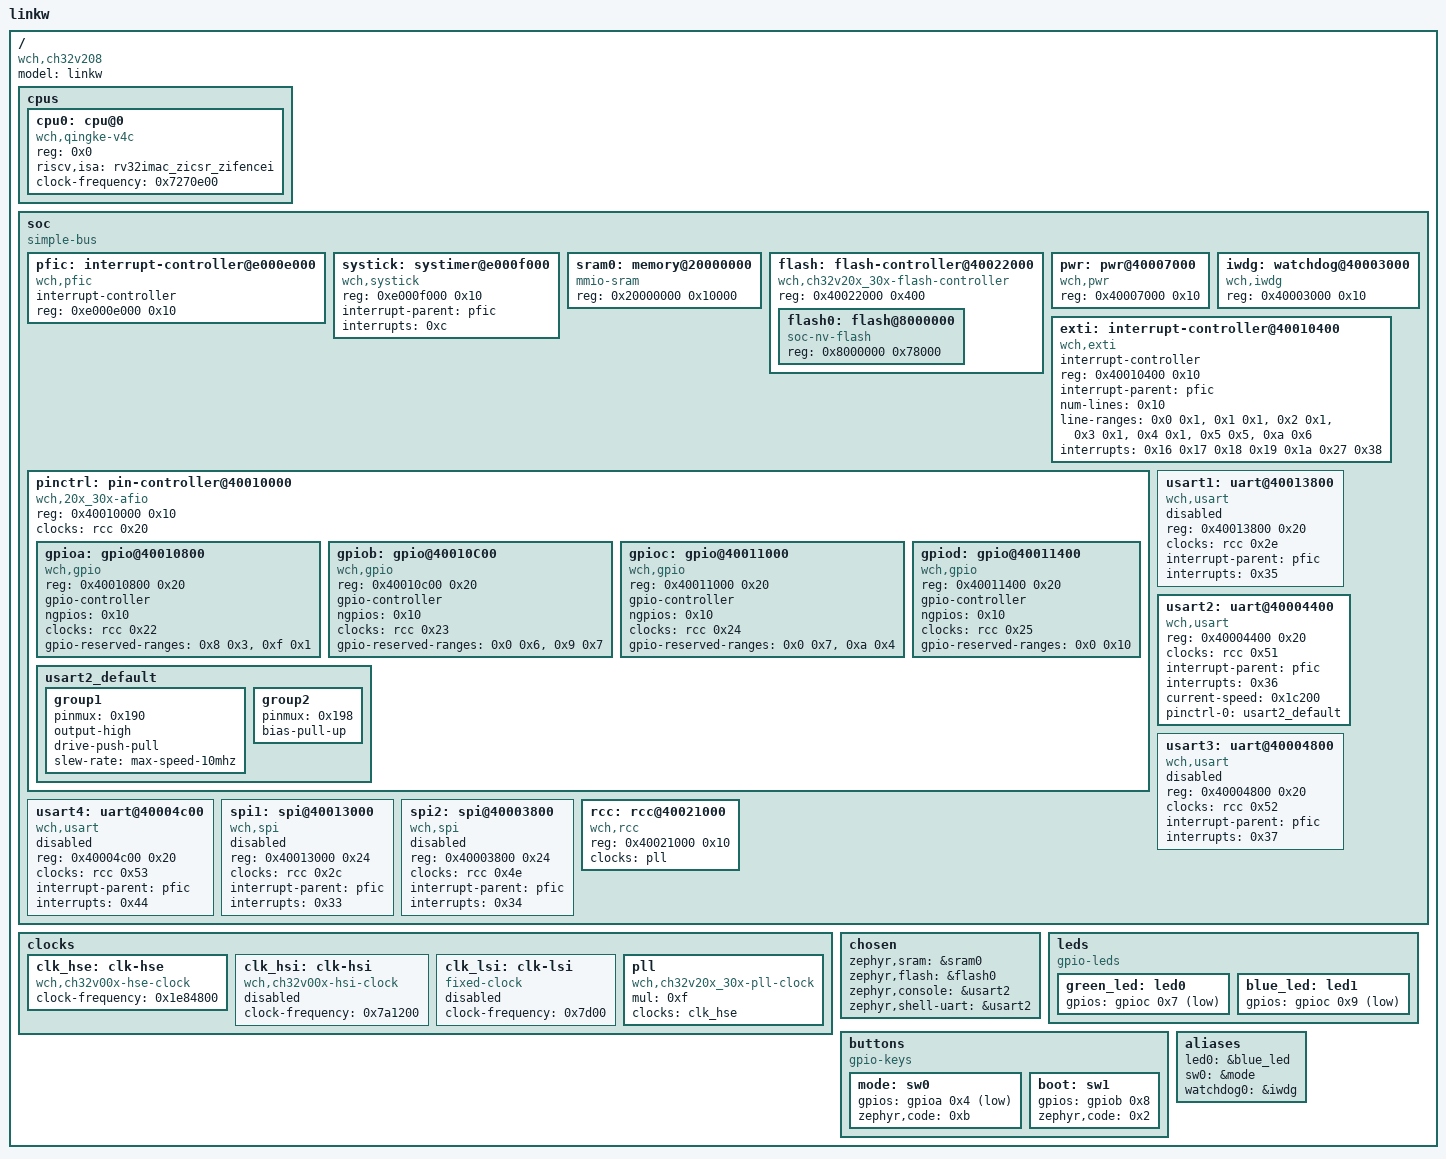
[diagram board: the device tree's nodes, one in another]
/dts-v1/;

/* node '/' defined in zephyr/dts/riscv/wch/qingke-v4c.dtsi:7 */
/ {
	#address-cells = < 0x1 >;    /* in zephyr/dts/riscv/wch/qingke-v4c.dtsi:8 */
	#size-cells = < 0x1 >;       /* in zephyr/dts/riscv/wch/qingke-v4c.dtsi:9 */
	model = "linkw";             /* in zephyr/boards/wch/linkw/linkw.dts:14 */
	compatible = "wch,ch32v208"; /* in zephyr/boards/wch/linkw/linkw.dts:15 */

	/* node '/cpus' defined in zephyr/dts/riscv/wch/qingke-v4c.dtsi:11 */
	cpus {
		#address-cells = < 0x1 >; /* in zephyr/dts/riscv/wch/qingke-v4c.dtsi:12 */
		#size-cells = < 0x0 >;    /* in zephyr/dts/riscv/wch/qingke-v4c.dtsi:13 */

		/* node '/cpus/cpu@0' defined in zephyr/dts/riscv/wch/qingke-v4c.dtsi:15 */
		cpu0: cpu@0 {
			device_type = "cpu";                   /* in zephyr/dts/riscv/wch/qingke-v4c.dtsi:16 */
			compatible = "wch,qingke-v4c";         /* in zephyr/dts/riscv/wch/qingke-v4c.dtsi:17 */
			reg = < 0x0 >;                         /* in zephyr/dts/riscv/wch/qingke-v4c.dtsi:18 */
			riscv,isa = "rv32imac_zicsr_zifencei"; /* in zephyr/dts/riscv/wch/qingke-v4c.dtsi:19 */
			clock-frequency = < 0x7270e00 >;       /* in zephyr/dts/riscv/wch/ch32v208/ch32v208.dtsi:200 */
		};
	};

	/* node '/soc' defined in zephyr/dts/riscv/wch/qingke-v4c.dtsi:23 */
	soc {
		#address-cells = < 0x1 >;  /* in zephyr/dts/riscv/wch/qingke-v4c.dtsi:24 */
		#size-cells = < 0x1 >;     /* in zephyr/dts/riscv/wch/qingke-v4c.dtsi:25 */
		compatible = "simple-bus"; /* in zephyr/dts/riscv/wch/qingke-v4c.dtsi:26 */
		ranges;                    /* in zephyr/dts/riscv/wch/qingke-v4c.dtsi:27 */

		/* node '/soc/interrupt-controller@e000e000' defined in zephyr/dts/riscv/wch/qingke-v4c.dtsi:29 */
		pfic: interrupt-controller@e000e000 {
			compatible = "wch,pfic";    /* in zephyr/dts/riscv/wch/qingke-v4c.dtsi:30 */
			#address-cells = < 0x0 >;   /* in zephyr/dts/riscv/wch/qingke-v4c.dtsi:31 */
			#interrupt-cells = < 0x1 >; /* in zephyr/dts/riscv/wch/qingke-v4c.dtsi:32 */
			interrupt-controller;       /* in zephyr/dts/riscv/wch/qingke-v4c.dtsi:33 */
			reg = < 0xe000e000 0x10 >;  /* in zephyr/dts/riscv/wch/qingke-v4c.dtsi:34 */
			status = "okay";            /* in zephyr/dts/riscv/wch/qingke-v4c.dtsi:35 */
			phandle = < 0x1 >;          /* in zephyr/dts/riscv/wch/qingke-v4c.dtsi:42 */
		};

		/* node '/soc/systimer@e000f000' defined in zephyr/dts/riscv/wch/qingke-v4c.dtsi:38 */
		systick: systimer@e000f000 {
			compatible = "wch,systick";   /* in zephyr/dts/riscv/wch/qingke-v4c.dtsi:39 */
			reg = < 0xe000f000 0x10 >;    /* in zephyr/dts/riscv/wch/qingke-v4c.dtsi:40 */
			status = "okay";              /* in zephyr/dts/riscv/wch/qingke-v4c.dtsi:41 */
			interrupt-parent = < &pfic >; /* in zephyr/dts/riscv/wch/qingke-v4c.dtsi:42 */
			interrupts = < 0xc >;         /* in zephyr/dts/riscv/wch/qingke-v4c.dtsi:43 */
		};

		/* node '/soc/memory@20000000' defined in zephyr/dts/riscv/wch/ch32v208/ch32v208.dtsi:46 */
		sram0: memory@20000000 {
			compatible = "mmio-sram";     /* in zephyr/dts/riscv/wch/ch32v208/ch32v208.dtsi:47 */
			reg = < 0x20000000 0x10000 >; /* in zephyr/dts/riscv/wch/ch32v208/ch32v208.dtsi:48 */
		};

		/* node '/soc/flash-controller@40022000' defined in zephyr/dts/riscv/wch/ch32v208/ch32v208.dtsi:51 */
		flash: flash-controller@40022000 {
			compatible = "wch,ch32v20x_30x-flash-controller"; /* in zephyr/dts/riscv/wch/ch32v208/ch32v208.dtsi:52 */
			reg = < 0x40022000 0x400 >;                       /* in zephyr/dts/riscv/wch/ch32v208/ch32v208.dtsi:53 */
			#address-cells = < 0x1 >;                         /* in zephyr/dts/riscv/wch/ch32v208/ch32v208.dtsi:54 */
			#size-cells = < 0x1 >;                            /* in zephyr/dts/riscv/wch/ch32v208/ch32v208.dtsi:55 */

			/* node '/soc/flash-controller@40022000/flash@8000000' defined in zephyr/dts/riscv/wch/ch32v208/ch32v208.dtsi:57 */
			flash0: flash@8000000 {
				compatible = "soc-nv-flash"; /* in zephyr/dts/riscv/wch/ch32v208/ch32v208.dtsi:58 */
				reg = < 0x8000000 0x78000 >; /* in zephyr/dts/riscv/wch/ch32v208/ch32v208.dtsi:59 */
			};
		};

		/* node '/soc/pwr@40007000' defined in zephyr/dts/riscv/wch/ch32v208/ch32v208.dtsi:63 */
		pwr: pwr@40007000 {
			compatible = "wch,pwr";    /* in zephyr/dts/riscv/wch/ch32v208/ch32v208.dtsi:64 */
			reg = < 0x40007000 0x10 >; /* in zephyr/dts/riscv/wch/ch32v208/ch32v208.dtsi:65 */
		};

		/* node '/soc/watchdog@40003000' defined in zephyr/dts/riscv/wch/ch32v208/ch32v208.dtsi:68 */
		iwdg: watchdog@40003000 {
			compatible = "wch,iwdg";   /* in zephyr/dts/riscv/wch/ch32v208/ch32v208.dtsi:69 */
			reg = < 0x40003000 0x10 >; /* in zephyr/dts/riscv/wch/ch32v208/ch32v208.dtsi:70 */
			status = "okay";           /* in zephyr/boards/wch/linkw/linkw.dts:92 */
		};

		/* node '/soc/interrupt-controller@40010400' defined in zephyr/dts/riscv/wch/ch32v208/ch32v208.dtsi:74 */
		exti: interrupt-controller@40010400 {
			compatible = "wch,exti";                             /* in zephyr/dts/riscv/wch/ch32v208/ch32v208.dtsi:75 */
			interrupt-controller;                                /* in zephyr/dts/riscv/wch/ch32v208/ch32v208.dtsi:76 */
			#interrupt-cells = < 0x1 >;                          /* in zephyr/dts/riscv/wch/ch32v208/ch32v208.dtsi:77 */
			reg = < 0x40010400 0x10 >;                           /* in zephyr/dts/riscv/wch/ch32v208/ch32v208.dtsi:78 */
			interrupt-parent = < &pfic >;                        /* in zephyr/dts/riscv/wch/ch32v208/ch32v208.dtsi:79 */
			num-lines = < 0x10 >;                                /* in zephyr/dts/riscv/wch/ch32v208/ch32v208.dtsi:80 */
			line-ranges = < 0x0 0x1 >,
			              < 0x1 0x1 >,
			              < 0x2 0x1 >,
			              < 0x3 0x1 >,
			              < 0x4 0x1 >,
			              < 0x5 0x5 >,
			              < 0xa 0x6 >;                           /* in zephyr/dts/riscv/wch/ch32v208/ch32v208.dtsi:81 */
			interrupts = < 0x16 0x17 0x18 0x19 0x1a 0x27 0x38 >; /* in zephyr/dts/riscv/wch/ch32v208/ch32v208.dtsi:83 */
			interrupt-names = "line0",
			                  "line1",
			                  "line2",
			                  "line3",
			                  "line4",
			                  "line5-9",
			                  "line10-15";                       /* in zephyr/dts/riscv/wch/ch32v208/ch32v208.dtsi:84 */
			status = "okay";                                     /* in zephyr/boards/wch/linkw/linkw.dts:73 */
		};

		/* node '/soc/pin-controller@40010000' defined in zephyr/dts/riscv/wch/ch32v208/ch32v208.dtsi:89 */
		pinctrl: pin-controller@40010000 {
			compatible = "wch,20x_30x-afio"; /* in zephyr/dts/riscv/wch/ch32v208/ch32v208.dtsi:90 */
			reg = < 0x40010000 0x10 >;       /* in zephyr/dts/riscv/wch/ch32v208/ch32v208.dtsi:91 */
			#address-cells = < 0x1 >;        /* in zephyr/dts/riscv/wch/ch32v208/ch32v208.dtsi:92 */
			#size-cells = < 0x1 >;           /* in zephyr/dts/riscv/wch/ch32v208/ch32v208.dtsi:93 */
			clocks = < &rcc 0x20 >;          /* in zephyr/dts/riscv/wch/ch32v208/ch32v208.dtsi:94 */

			/* node '/soc/pin-controller@40010000/gpio@40010800' defined in zephyr/dts/riscv/wch/ch32v208/ch32v208.dtsi:96 */
			gpioa: gpio@40010800 {
				compatible = "wch,gpio";            /* in zephyr/dts/riscv/wch/ch32v208/ch32v208.dtsi:97 */
				reg = < 0x40010800 0x20 >;          /* in zephyr/dts/riscv/wch/ch32v208/ch32v208.dtsi:98 */
				gpio-controller;                    /* in zephyr/dts/riscv/wch/ch32v208/ch32v208.dtsi:99 */
				#gpio-cells = < 0x2 >;              /* in zephyr/dts/riscv/wch/ch32v208/ch32v208.dtsi:100 */
				ngpios = < 0x10 >;                  /* in zephyr/dts/riscv/wch/ch32v208/ch32v208.dtsi:101 */
				clocks = < &rcc 0x22 >;             /* in zephyr/dts/riscv/wch/ch32v208/ch32v208.dtsi:102 */
				gpio-reserved-ranges = < 0x8 0x3 >,
				                       < 0xf 0x1 >; /* in zephyr/dts/riscv/wch/ch32v208/ch32v208gbu.dtsi:10 */
				status = "okay";                    /* in zephyr/boards/wch/linkw/linkw.dts:77 */
				phandle = < 0x7 >;                  /* in zephyr/boards/wch/linkw/linkw.dts:41 */
			};

			/* node '/soc/pin-controller@40010000/gpio@40010C00' defined in zephyr/dts/riscv/wch/ch32v208/ch32v208.dtsi:105 */
			gpiob: gpio@40010C00 {
				compatible = "wch,gpio";            /* in zephyr/dts/riscv/wch/ch32v208/ch32v208.dtsi:106 */
				reg = < 0x40010c00 0x20 >;          /* in zephyr/dts/riscv/wch/ch32v208/ch32v208.dtsi:107 */
				gpio-controller;                    /* in zephyr/dts/riscv/wch/ch32v208/ch32v208.dtsi:108 */
				#gpio-cells = < 0x2 >;              /* in zephyr/dts/riscv/wch/ch32v208/ch32v208.dtsi:109 */
				ngpios = < 0x10 >;                  /* in zephyr/dts/riscv/wch/ch32v208/ch32v208.dtsi:110 */
				clocks = < &rcc 0x23 >;             /* in zephyr/dts/riscv/wch/ch32v208/ch32v208.dtsi:111 */
				gpio-reserved-ranges = < 0x0 0x6 >,
				                       < 0x9 0x7 >; /* in zephyr/dts/riscv/wch/ch32v208/ch32v208gbu.dtsi:14 */
				phandle = < 0x8 >;                  /* in zephyr/boards/wch/linkw/linkw.dts:46 */
			};

			/* node '/soc/pin-controller@40010000/gpio@40011000' defined in zephyr/dts/riscv/wch/ch32v208/ch32v208.dtsi:114 */
			gpioc: gpio@40011000 {
				compatible = "wch,gpio";            /* in zephyr/dts/riscv/wch/ch32v208/ch32v208.dtsi:115 */
				reg = < 0x40011000 0x20 >;          /* in zephyr/dts/riscv/wch/ch32v208/ch32v208.dtsi:116 */
				gpio-controller;                    /* in zephyr/dts/riscv/wch/ch32v208/ch32v208.dtsi:117 */
				#gpio-cells = < 0x2 >;              /* in zephyr/dts/riscv/wch/ch32v208/ch32v208.dtsi:118 */
				ngpios = < 0x10 >;                  /* in zephyr/dts/riscv/wch/ch32v208/ch32v208.dtsi:119 */
				clocks = < &rcc 0x24 >;             /* in zephyr/dts/riscv/wch/ch32v208/ch32v208.dtsi:120 */
				gpio-reserved-ranges = < 0x0 0x7 >,
				                       < 0xa 0x4 >; /* in zephyr/dts/riscv/wch/ch32v208/ch32v208gbu.dtsi:18 */
				status = "okay";                    /* in zephyr/boards/wch/linkw/linkw.dts:81 */
				phandle = < 0x6 >;                  /* in zephyr/boards/wch/linkw/linkw.dts:29 */
			};

			/* node '/soc/pin-controller@40010000/gpio@40011400' defined in zephyr/dts/riscv/wch/ch32v208/ch32v208.dtsi:123 */
			gpiod: gpio@40011400 {
				compatible = "wch,gpio";             /* in zephyr/dts/riscv/wch/ch32v208/ch32v208.dtsi:124 */
				reg = < 0x40011400 0x20 >;           /* in zephyr/dts/riscv/wch/ch32v208/ch32v208.dtsi:125 */
				gpio-controller;                     /* in zephyr/dts/riscv/wch/ch32v208/ch32v208.dtsi:126 */
				#gpio-cells = < 0x2 >;               /* in zephyr/dts/riscv/wch/ch32v208/ch32v208.dtsi:127 */
				ngpios = < 0x10 >;                   /* in zephyr/dts/riscv/wch/ch32v208/ch32v208.dtsi:128 */
				clocks = < &rcc 0x25 >;              /* in zephyr/dts/riscv/wch/ch32v208/ch32v208.dtsi:129 */
				gpio-reserved-ranges = < 0x0 0x10 >; /* in zephyr/dts/riscv/wch/ch32v208/ch32v208gbu.dtsi:22 */
			};

			/* node '/soc/pin-controller@40010000/usart2_default' defined in zephyr/boards/wch/linkw/linkw-pinctrl.dtsi:9 */
			usart2_default: usart2_default {
				phandle = < 0x3 >; /* in zephyr/boards/wch/linkw/linkw.dts:87 */

				/* node '/soc/pin-controller@40010000/usart2_default/group1' defined in zephyr/boards/wch/linkw/linkw-pinctrl.dtsi:10 */
				group1 {
					pinmux = < 0x190 >;            /* in zephyr/boards/wch/linkw/linkw-pinctrl.dtsi:11 */
					output-high;                   /* in zephyr/boards/wch/linkw/linkw-pinctrl.dtsi:12 */
					drive-push-pull;               /* in zephyr/boards/wch/linkw/linkw-pinctrl.dtsi:13 */
					slew-rate = "max-speed-10mhz"; /* in zephyr/boards/wch/linkw/linkw-pinctrl.dtsi:14 */
				};

				/* node '/soc/pin-controller@40010000/usart2_default/group2' defined in zephyr/boards/wch/linkw/linkw-pinctrl.dtsi:17 */
				group2 {
					pinmux = < 0x198 >; /* in zephyr/boards/wch/linkw/linkw-pinctrl.dtsi:18 */
					bias-pull-up;       /* in zephyr/boards/wch/linkw/linkw-pinctrl.dtsi:19 */
				};
			};
		};

		/* node '/soc/uart@40013800' defined in zephyr/dts/riscv/wch/ch32v208/ch32v208.dtsi:133 */
		usart1: uart@40013800 {
			compatible = "wch,usart";     /* in zephyr/dts/riscv/wch/ch32v208/ch32v208.dtsi:134 */
			reg = < 0x40013800 0x20 >;    /* in zephyr/dts/riscv/wch/ch32v208/ch32v208.dtsi:135 */
			clocks = < &rcc 0x2e >;       /* in zephyr/dts/riscv/wch/ch32v208/ch32v208.dtsi:136 */
			interrupt-parent = < &pfic >; /* in zephyr/dts/riscv/wch/ch32v208/ch32v208.dtsi:137 */
			interrupts = < 0x35 >;        /* in zephyr/dts/riscv/wch/ch32v208/ch32v208.dtsi:138 */
			status = "disabled";          /* in zephyr/dts/riscv/wch/ch32v208/ch32v208.dtsi:139 */
		};

		/* node '/soc/uart@40004400' defined in zephyr/dts/riscv/wch/ch32v208/ch32v208.dtsi:142 */
		usart2: uart@40004400 {
			compatible = "wch,usart";        /* in zephyr/dts/riscv/wch/ch32v208/ch32v208.dtsi:143 */
			reg = < 0x40004400 0x20 >;       /* in zephyr/dts/riscv/wch/ch32v208/ch32v208.dtsi:144 */
			clocks = < &rcc 0x51 >;          /* in zephyr/dts/riscv/wch/ch32v208/ch32v208.dtsi:145 */
			interrupt-parent = < &pfic >;    /* in zephyr/dts/riscv/wch/ch32v208/ch32v208.dtsi:146 */
			interrupts = < 0x36 >;           /* in zephyr/dts/riscv/wch/ch32v208/ch32v208.dtsi:147 */
			status = "okay";                 /* in zephyr/boards/wch/linkw/linkw.dts:85 */
			current-speed = < 0x1c200 >;     /* in zephyr/boards/wch/linkw/linkw.dts:86 */
			pinctrl-0 = < &usart2_default >; /* in zephyr/boards/wch/linkw/linkw.dts:87 */
			pinctrl-names = "default";       /* in zephyr/boards/wch/linkw/linkw.dts:88 */
		};

		/* node '/soc/uart@40004800' defined in zephyr/dts/riscv/wch/ch32v208/ch32v208.dtsi:151 */
		usart3: uart@40004800 {
			compatible = "wch,usart";     /* in zephyr/dts/riscv/wch/ch32v208/ch32v208.dtsi:152 */
			reg = < 0x40004800 0x20 >;    /* in zephyr/dts/riscv/wch/ch32v208/ch32v208.dtsi:153 */
			clocks = < &rcc 0x52 >;       /* in zephyr/dts/riscv/wch/ch32v208/ch32v208.dtsi:154 */
			interrupt-parent = < &pfic >; /* in zephyr/dts/riscv/wch/ch32v208/ch32v208.dtsi:155 */
			interrupts = < 0x37 >;        /* in zephyr/dts/riscv/wch/ch32v208/ch32v208.dtsi:156 */
			status = "disabled";          /* in zephyr/dts/riscv/wch/ch32v208/ch32v208.dtsi:157 */
		};

		/* node '/soc/uart@40004c00' defined in zephyr/dts/riscv/wch/ch32v208/ch32v208.dtsi:160 */
		usart4: uart@40004c00 {
			compatible = "wch,usart";     /* in zephyr/dts/riscv/wch/ch32v208/ch32v208.dtsi:161 */
			reg = < 0x40004c00 0x20 >;    /* in zephyr/dts/riscv/wch/ch32v208/ch32v208.dtsi:162 */
			clocks = < &rcc 0x53 >;       /* in zephyr/dts/riscv/wch/ch32v208/ch32v208.dtsi:163 */
			interrupt-parent = < &pfic >; /* in zephyr/dts/riscv/wch/ch32v208/ch32v208.dtsi:164 */
			interrupts = < 0x44 >;        /* in zephyr/dts/riscv/wch/ch32v208/ch32v208.dtsi:165 */
			status = "disabled";          /* in zephyr/dts/riscv/wch/ch32v208/ch32v208.dtsi:166 */
		};

		/* node '/soc/spi@40013000' defined in zephyr/dts/riscv/wch/ch32v208/ch32v208.dtsi:169 */
		spi1: spi@40013000 {
			compatible = "wch,spi";       /* in zephyr/dts/riscv/wch/ch32v208/ch32v208.dtsi:170 */
			reg = < 0x40013000 0x24 >;    /* in zephyr/dts/riscv/wch/ch32v208/ch32v208.dtsi:171 */
			clocks = < &rcc 0x2c >;       /* in zephyr/dts/riscv/wch/ch32v208/ch32v208.dtsi:172 */
			interrupt-parent = < &pfic >; /* in zephyr/dts/riscv/wch/ch32v208/ch32v208.dtsi:173 */
			interrupts = < 0x33 >;        /* in zephyr/dts/riscv/wch/ch32v208/ch32v208.dtsi:174 */
			status = "disabled";          /* in zephyr/dts/riscv/wch/ch32v208/ch32v208.dtsi:175 */
			#address-cells = < 0x1 >;     /* in zephyr/dts/riscv/wch/ch32v208/ch32v208.dtsi:176 */
			#size-cells = < 0x0 >;        /* in zephyr/dts/riscv/wch/ch32v208/ch32v208.dtsi:177 */
		};

		/* node '/soc/spi@40003800' defined in zephyr/dts/riscv/wch/ch32v208/ch32v208.dtsi:180 */
		spi2: spi@40003800 {
			compatible = "wch,spi";       /* in zephyr/dts/riscv/wch/ch32v208/ch32v208.dtsi:181 */
			reg = < 0x40003800 0x24 >;    /* in zephyr/dts/riscv/wch/ch32v208/ch32v208.dtsi:182 */
			clocks = < &rcc 0x4e >;       /* in zephyr/dts/riscv/wch/ch32v208/ch32v208.dtsi:183 */
			interrupt-parent = < &pfic >; /* in zephyr/dts/riscv/wch/ch32v208/ch32v208.dtsi:184 */
			interrupts = < 0x34 >;        /* in zephyr/dts/riscv/wch/ch32v208/ch32v208.dtsi:185 */
			status = "disabled";          /* in zephyr/dts/riscv/wch/ch32v208/ch32v208.dtsi:186 */
			#address-cells = < 0x1 >;     /* in zephyr/dts/riscv/wch/ch32v208/ch32v208.dtsi:187 */
			#size-cells = < 0x0 >;        /* in zephyr/dts/riscv/wch/ch32v208/ch32v208.dtsi:188 */
		};

		/* node '/soc/rcc@40021000' defined in zephyr/dts/riscv/wch/ch32v208/ch32v208.dtsi:191 */
		rcc: rcc@40021000 {
			compatible = "wch,rcc";    /* in zephyr/dts/riscv/wch/ch32v208/ch32v208.dtsi:192 */
			reg = < 0x40021000 0x10 >; /* in zephyr/dts/riscv/wch/ch32v208/ch32v208.dtsi:193 */
			#clock-cells = < 0x1 >;    /* in zephyr/dts/riscv/wch/ch32v208/ch32v208.dtsi:194 */
			clocks = < &pll >;         /* in zephyr/boards/wch/linkw/linkw.dts:69 */
			phandle = < 0x2 >;         /* in zephyr/dts/riscv/wch/ch32v208/ch32v208.dtsi:94 */
		};
	};

	/* node '/clocks' defined in zephyr/dts/riscv/wch/ch32v208/ch32v208.dtsi:15 */
	clocks {

		/* node '/clocks/clk-hse' defined in zephyr/dts/riscv/wch/ch32v208/ch32v208.dtsi:16 */
		clk_hse: clk-hse {
			#clock-cells = < 0x0 >;                /* in zephyr/dts/riscv/wch/ch32v208/ch32v208.dtsi:17 */
			compatible = "wch,ch32v00x-hse-clock"; /* in zephyr/dts/riscv/wch/ch32v208/ch32v208.dtsi:18 */
			clock-frequency = < 0x1e84800 >;       /* in zephyr/boards/wch/linkw/linkw.dts:59 */
			status = "okay";                       /* in zephyr/boards/wch/linkw/linkw.dts:60 */
			phandle = < 0x5 >;                     /* in zephyr/boards/wch/linkw/linkw.dts:64 */
		};

		/* node '/clocks/clk-hsi' defined in zephyr/dts/riscv/wch/ch32v208/ch32v208.dtsi:23 */
		clk_hsi: clk-hsi {
			#clock-cells = < 0x0 >;                /* in zephyr/dts/riscv/wch/ch32v208/ch32v208.dtsi:24 */
			compatible = "wch,ch32v00x-hsi-clock"; /* in zephyr/dts/riscv/wch/ch32v208/ch32v208.dtsi:25 */
			clock-frequency = < 0x7a1200 >;        /* in zephyr/dts/riscv/wch/ch32v208/ch32v208.dtsi:26 */
			status = "disabled";                   /* in zephyr/dts/riscv/wch/ch32v208/ch32v208.dtsi:27 */
		};

		/* node '/clocks/clk-lsi' defined in zephyr/dts/riscv/wch/ch32v208/ch32v208.dtsi:30 */
		clk_lsi: clk-lsi {
			#clock-cells = < 0x0 >;       /* in zephyr/dts/riscv/wch/ch32v208/ch32v208.dtsi:31 */
			compatible = "fixed-clock";   /* in zephyr/dts/riscv/wch/ch32v208/ch32v208.dtsi:32 */
			clock-frequency = < 0x7d00 >; /* in zephyr/dts/riscv/wch/ch32v208/ch32v208.dtsi:33 */
			status = "disabled";          /* in zephyr/dts/riscv/wch/ch32v208/ch32v208.dtsi:34 */
		};

		/* node '/clocks/pll' defined in zephyr/dts/riscv/wch/ch32v208/ch32v208.dtsi:37 */
		pll: pll {
			#clock-cells = < 0x0 >;                    /* in zephyr/dts/riscv/wch/ch32v208/ch32v208.dtsi:38 */
			compatible = "wch,ch32v20x_30x-pll-clock"; /* in zephyr/dts/riscv/wch/ch32v208/ch32v208.dtsi:39 */
			mul = < 0xf >;                             /* in zephyr/dts/riscv/wch/ch32v208/ch32v208.dtsi:40 */
			clocks = < &clk_hse >;                     /* in zephyr/boards/wch/linkw/linkw.dts:64 */
			status = "okay";                           /* in zephyr/boards/wch/linkw/linkw.dts:65 */
			phandle = < 0x4 >;                         /* in zephyr/boards/wch/linkw/linkw.dts:69 */
		};
	};

	/* node '/chosen' defined in zephyr/boards/wch/linkw/linkw.dts:17 */
	chosen {
		zephyr,sram = &sram0;        /* in zephyr/boards/wch/linkw/linkw.dts:18 */
		zephyr,flash = &flash0;      /* in zephyr/boards/wch/linkw/linkw.dts:19 */
		zephyr,console = &usart2;    /* in zephyr/boards/wch/linkw/linkw.dts:20 */
		zephyr,shell-uart = &usart2; /* in zephyr/boards/wch/linkw/linkw.dts:21 */
	};

	/* node '/leds' defined in zephyr/boards/wch/linkw/linkw.dts:24 */
	leds {
		compatible = "gpio-leds"; /* in zephyr/boards/wch/linkw/linkw.dts:25 */
		status = "okay";          /* in zephyr/boards/wch/linkw/linkw.dts:26 */

		/* node '/leds/led0' defined in zephyr/boards/wch/linkw/linkw.dts:28 */
		green_led: led0 {
			gpios = < &gpioc 0x7 0x1 >; /* in zephyr/boards/wch/linkw/linkw.dts:29 */
		};

		/* node '/leds/led1' defined in zephyr/boards/wch/linkw/linkw.dts:32 */
		blue_led: led1 {
			gpios = < &gpioc 0x9 0x1 >; /* in zephyr/boards/wch/linkw/linkw.dts:33 */
		};
	};

	/* node '/buttons' defined in zephyr/boards/wch/linkw/linkw.dts:37 */
	buttons {
		compatible = "gpio-keys"; /* in zephyr/boards/wch/linkw/linkw.dts:38 */

		/* node '/buttons/sw0' defined in zephyr/boards/wch/linkw/linkw.dts:40 */
		mode: sw0 {
			gpios = < &gpioa 0x4 0x1 >; /* in zephyr/boards/wch/linkw/linkw.dts:41 */
			zephyr,code = < 0xb >;      /* in zephyr/boards/wch/linkw/linkw.dts:42 */
		};

		/* node '/buttons/sw1' defined in zephyr/boards/wch/linkw/linkw.dts:45 */
		boot: sw1 {
			gpios = < &gpiob 0x8 0x0 >; /* in zephyr/boards/wch/linkw/linkw.dts:46 */
			zephyr,code = < 0x2 >;      /* in zephyr/boards/wch/linkw/linkw.dts:47 */
		};
	};

	/* node '/aliases' defined in zephyr/boards/wch/linkw/linkw.dts:51 */
	aliases {
		led0 = &blue_led;  /* in zephyr/boards/wch/linkw/linkw.dts:52 */
		sw0 = &mode;       /* in zephyr/boards/wch/linkw/linkw.dts:53 */
		watchdog0 = &iwdg; /* in zephyr/boards/wch/linkw/linkw.dts:54 */
	};
};
